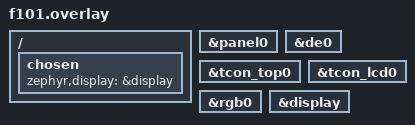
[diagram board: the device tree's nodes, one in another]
/*
 * The RGB LCD pipeline of the board comes back (the base overlay switches it
 * off). The panel uses PD0..PD22 and PE6/PE7: PWM0 (PD6 PD7 PD8 PB3) would take
 * some of the same pins, so analogWrite() falls back to digital.
 */

/ {
	chosen {
		zephyr,display = &display;
	};
};

&panel0 { status = "okay"; };
&de0 { status = "okay"; };
&tcon_top0 { status = "okay"; };
&tcon_lcd0 { status = "okay"; };
&rgb0 { status = "okay"; };
&display { status = "okay"; };
